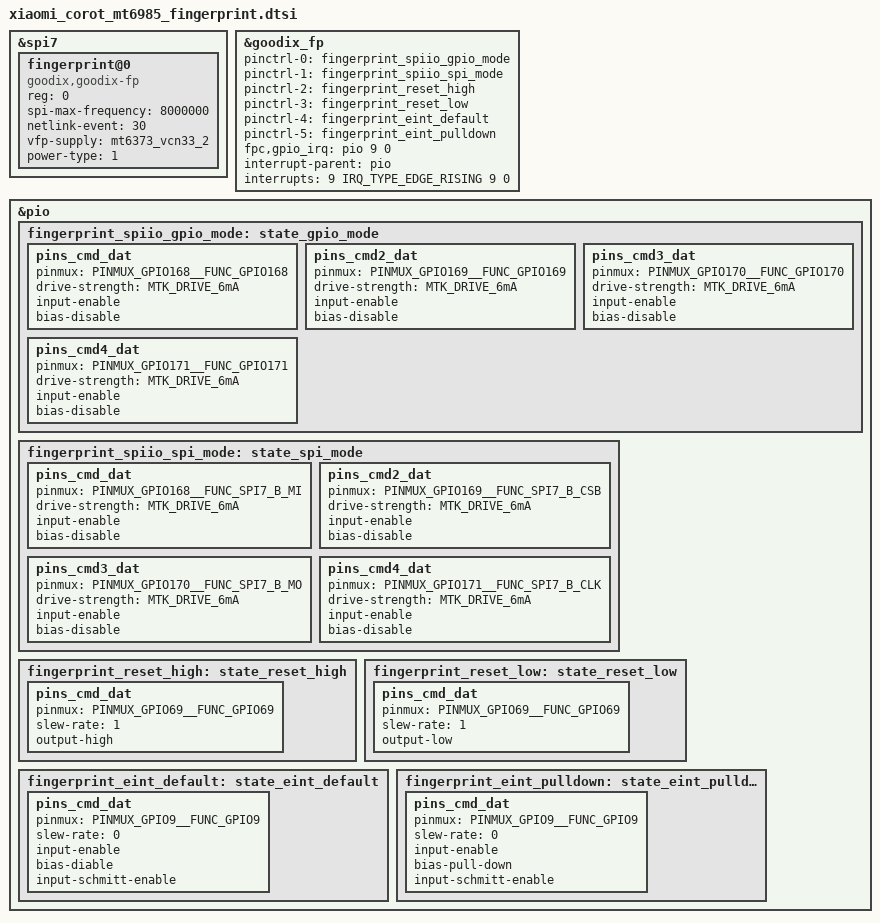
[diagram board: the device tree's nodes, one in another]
// SPDX-License-Identifier: (GPL-2.0 OR MIT)
/*
 * Copyright (C) 2020 MediaTek Inc.
 * Copyright (C) 2022-2023 XiaoMi, Inc.
 */

/* fingerprint start */


&spi7 {
	#address-cells = <1>;
	#size-cells = <0>;
	fingerprint@0 {
		compatible = "goodix,goodix-fp";
		reg = <0>;
		spi-max-frequency = <8000000>;
		netlink-event = <30>;
		vfp-supply = <&mt6373_vcn33_2>;
		//vibr-supply = <&mt6368_vibr>;
		power-type = <1>;
		status = "okay";
	};
};

&goodix_fp {
	pinctrl-names = "spiio_gpio_mode", "spiio_spi_mode", "reset_high", "reset_low", "eint_default", "eint_pulldown";
	pinctrl-0 = <&fingerprint_spiio_gpio_mode>;
	pinctrl-1 = <&fingerprint_spiio_spi_mode>;
	pinctrl-2 = <&fingerprint_reset_high>;
	pinctrl-3 = <&fingerprint_reset_low>;
	pinctrl-4 = <&fingerprint_eint_default>;
	pinctrl-5 = <&fingerprint_eint_pulldown>;
	fpc,gpio_irq = <&pio 9 0>;
	interrupt-parent = <&pio>;
	interrupts = <9 IRQ_TYPE_EDGE_RISING 9 0>;
	status = "okay";
};

&pio {
	fingerprint_spiio_gpio_mode: state_gpio_mode {
		pins_cmd_dat {
			pinmux = <PINMUX_GPIO168__FUNC_GPIO168>;
            drive-strength = <MTK_DRIVE_6mA>;
			input-enable;
			bias-disable;
		};
		pins_cmd2_dat {
			pinmux = <PINMUX_GPIO169__FUNC_GPIO169>;
            drive-strength = <MTK_DRIVE_6mA>;
			input-enable;
			bias-disable;
		};
		pins_cmd3_dat {
			pinmux = <PINMUX_GPIO170__FUNC_GPIO170>;
            drive-strength = <MTK_DRIVE_6mA>;
			input-enable;
			bias-disable;
		};
		pins_cmd4_dat {
			pinmux = <PINMUX_GPIO171__FUNC_GPIO171>;
            drive-strength = <MTK_DRIVE_6mA>;
			input-enable;
			bias-disable;
		};
	};
	fingerprint_spiio_spi_mode: state_spi_mode {
		pins_cmd_dat {
			pinmux = <PINMUX_GPIO168__FUNC_SPI7_B_MI>;
            drive-strength = <MTK_DRIVE_6mA>;
			input-enable;
			bias-disable;
		};
		pins_cmd2_dat {
			pinmux = <PINMUX_GPIO169__FUNC_SPI7_B_CSB>;
            drive-strength = <MTK_DRIVE_6mA>;
			input-enable;
			bias-disable;
		};
		pins_cmd3_dat {
			pinmux = <PINMUX_GPIO170__FUNC_SPI7_B_MO>;
            drive-strength = <MTK_DRIVE_6mA>;
			input-enable;
			bias-disable;
		};
		pins_cmd4_dat {
			pinmux = <PINMUX_GPIO171__FUNC_SPI7_B_CLK>;
            drive-strength = <MTK_DRIVE_6mA>;
			input-enable;
			bias-disable;
		};
	};

	fingerprint_reset_high: state_reset_high {
		pins_cmd_dat {
			pinmux = <PINMUX_GPIO69__FUNC_GPIO69>;
			slew-rate = <1>;
			output-high;
		};
	};
	fingerprint_reset_low: state_reset_low {
		pins_cmd_dat {
			pinmux = <PINMUX_GPIO69__FUNC_GPIO69>;
			slew-rate = <1>;
			output-low;
		};
	};
	fingerprint_eint_default: state_eint_default {
		pins_cmd_dat {
			pinmux = <PINMUX_GPIO9__FUNC_GPIO9>;
			slew-rate = <0>;
			input-enable;
			bias-diable;
			input-schmitt-enable;
		};
	};
	fingerprint_eint_pulldown: state_eint_pulldown {
		pins_cmd_dat {
			pinmux = <PINMUX_GPIO9__FUNC_GPIO9>;
			slew-rate = <0>;
			input-enable;
			bias-pull-down;
			input-schmitt-enable;
		};
	};
};

/* fingerprint end */
